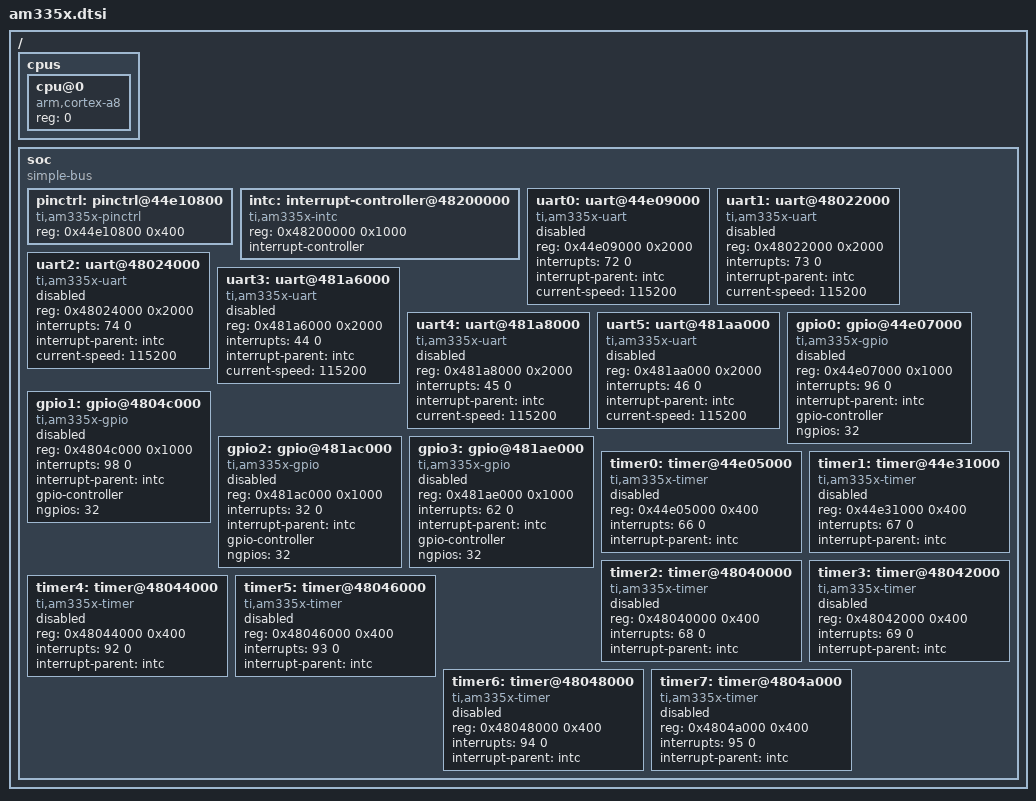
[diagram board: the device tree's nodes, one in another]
/* SPDX-License-Identifier: Apache-2.0 */

#include <arm/armv7-a.dtsi>
#include <dt-bindings/gpio/gpio.h>
#include <dt-bindings/pinctrl/am335x-pinctrl.h>
#include <mem.h>

/ {
	#address-cells = <1>;
	#size-cells = <1>;

	cpus {
		#address-cells = <1>;
		#size-cells = <0>;

		cpu@0 {
			device_type = "cpu";
			compatible = "arm,cortex-a8";
			reg = <0>;
		};
	};

	soc {
		#address-cells = <1>;
		#size-cells = <1>;
		compatible = "simple-bus";
		ranges;

		pinctrl: pinctrl@44e10800 {
			compatible = "ti,am335x-pinctrl";
			reg = <0x44e10800 0x400>;
			status = "okay";
		};

		intc: interrupt-controller@48200000 {
			compatible = "ti,am335x-intc";
			reg = <0x48200000 0x1000>;
			interrupt-controller;
			#interrupt-cells = <2>;
			status = "okay";
		};

		uart0: uart@44e09000 {
			compatible = "ti,am335x-uart";
			reg = <0x44e09000 0x2000>;
			interrupts = <72 0>;
			interrupt-parent = <&intc>;
			status = "disabled";
			current-speed = <115200>;
		};

		uart1: uart@48022000 {
			compatible = "ti,am335x-uart";
			reg = <0x48022000 0x2000>;
			interrupts = <73 0>;
			interrupt-parent = <&intc>;
			status = "disabled";
			current-speed = <115200>;
		};

		uart2: uart@48024000 {
			compatible = "ti,am335x-uart";
			reg = <0x48024000 0x2000>;
			interrupts = <74 0>;
			interrupt-parent = <&intc>;
			status = "disabled";
			current-speed = <115200>;
		};

		uart3: uart@481a6000 {
			compatible = "ti,am335x-uart";
			reg = <0x481a6000 0x2000>;
			interrupts = <44 0>;
			interrupt-parent = <&intc>;
			status = "disabled";
			current-speed = <115200>;
		};

		uart4: uart@481a8000 {
			compatible = "ti,am335x-uart";
			reg = <0x481a8000 0x2000>;
			interrupts = <45 0>;
			interrupt-parent = <&intc>;
			status = "disabled";
			current-speed = <115200>;
		};

		uart5: uart@481aa000 {
			compatible = "ti,am335x-uart";
			reg = <0x481aa000 0x2000>;
			interrupts = <46 0>;
			interrupt-parent = <&intc>;
			status = "disabled";
			current-speed = <115200>;
		};

		gpio0: gpio@44e07000 {
			compatible = "ti,am335x-gpio";
			reg = <0x44e07000 0x1000>;
			interrupts = <96 0>;
			interrupt-parent = <&intc>;
			gpio-controller;
			#gpio-cells = <2>;
			ngpios = <32>;
			status = "disabled";
		};

		gpio1: gpio@4804c000 {
			compatible = "ti,am335x-gpio";
			reg = <0x4804c000 0x1000>;
			interrupts = <98 0>;
			interrupt-parent = <&intc>;
			gpio-controller;
			#gpio-cells = <2>;
			ngpios = <32>;
			status = "disabled";
		};

		gpio2: gpio@481ac000 {
			compatible = "ti,am335x-gpio";
			reg = <0x481ac000 0x1000>;
			interrupts = <32 0>;
			interrupt-parent = <&intc>;
			gpio-controller;
			#gpio-cells = <2>;
			ngpios = <32>;
			status = "disabled";
		};

		gpio3: gpio@481ae000 {
			compatible = "ti,am335x-gpio";
			reg = <0x481ae000 0x1000>;
			interrupts = <62 0>;
			interrupt-parent = <&intc>;
			gpio-controller;
			#gpio-cells = <2>;
			ngpios = <32>;
			status = "disabled";
		};

		timer0: timer@44e05000 {
			compatible = "ti,am335x-timer";
			reg = <0x44e05000 0x400>;
			interrupts = <66 0>;
			interrupt-parent = <&intc>;
			status = "disabled";
		};

		timer1: timer@44e31000 {
			compatible = "ti,am335x-timer";
			reg = <0x44e31000 0x400>;
			interrupts = <67 0>;
			interrupt-parent = <&intc>;
			status = "disabled";
		};

		timer2: timer@48040000 {
			compatible = "ti,am335x-timer";
			reg = <0x48040000 0x400>;
			interrupts = <68 0>;
			interrupt-parent = <&intc>;
			status = "disabled";
		};

		timer3: timer@48042000 {
			compatible = "ti,am335x-timer";
			reg = <0x48042000 0x400>;
			interrupts = <69 0>;
			interrupt-parent = <&intc>;
			status = "disabled";
		};

		timer4: timer@48044000 {
			compatible = "ti,am335x-timer";
			reg = <0x48044000 0x400>;
			interrupts = <92 0>;
			interrupt-parent = <&intc>;
			status = "disabled";
		};

		timer5: timer@48046000 {
			compatible = "ti,am335x-timer";
			reg = <0x48046000 0x400>;
			interrupts = <93 0>;
			interrupt-parent = <&intc>;
			status = "disabled";
		};

		timer6: timer@48048000 {
			compatible = "ti,am335x-timer";
			reg = <0x48048000 0x400>;
			interrupts = <94 0>;
			interrupt-parent = <&intc>;
			status = "disabled";
		};

		timer7: timer@4804a000 {
			compatible = "ti,am335x-timer";
			reg = <0x4804a000 0x400>;
			interrupts = <95 0>;
			interrupt-parent = <&intc>;
			status = "disabled";
		};
	};
};
